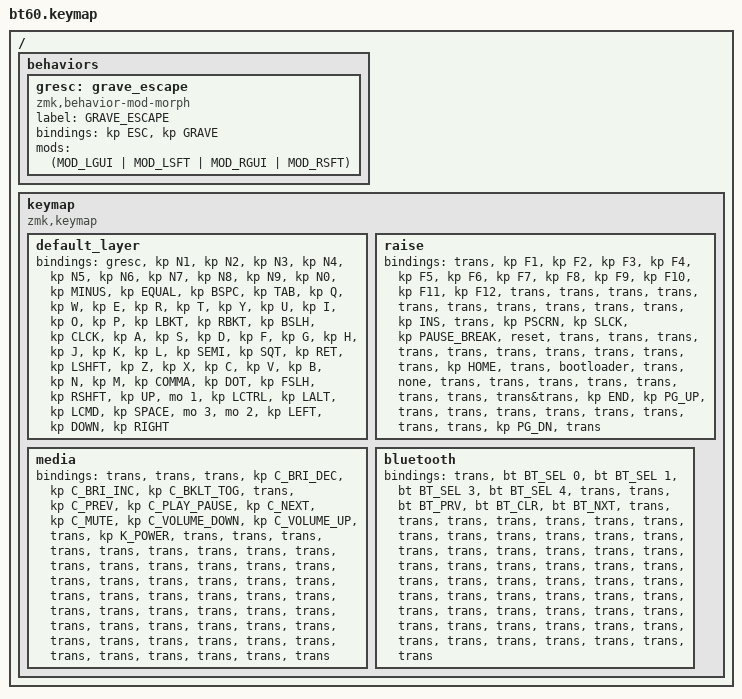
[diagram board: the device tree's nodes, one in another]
/*
 * Copyright (c) 2020 The ZMK Contributors
 *
 * SPDX-License-Identifier: MIT
 */


/* THIS FILE WAS GENERATED!
 *
 * This file was generated automatically. You may or may not want to
 * edit it directly.
 */

#include <behaviors.dtsi>
#include <dt-bindings/zmk/keys.h>

#include <dt-bindings/zmk/bt.h>
#include <dt-bindings/zmk/ext_power.h>

/ {
  
 behaviors
    {
    gresc:
        grave_escape
        {
            compatible = "zmk,behavior-mod-morph";
            label = "GRAVE_ESCAPE";
            #binding-cells = < 0>;
            bindings = <&kp ESC>, <&kp GRAVE>;
            mods = <(MOD_LGUI | MOD_LSFT | MOD_RGUI | MOD_RSFT)>;
        };
    };

    keymap {
        compatible = "zmk,keymap";


        default_layer {
            bindings = <
              &gresc &kp N1 &kp N2 &kp N3 &kp N4 &kp N5 &kp N6 &kp N7 &kp N8 &kp N9 &kp N0 &kp MINUS &kp EQUAL &kp BSPC

              &kp TAB &kp Q &kp W &kp E &kp R &kp T &kp Y &kp U &kp I &kp O &kp P &kp LBKT &kp RBKT &kp BSLH 

              &kp CLCK &kp A &kp S &kp D &kp F &kp G &kp H &kp J &kp K &kp L &kp SEMI &kp SQT &kp RET 

              &kp LSHFT &kp Z &kp X &kp C &kp V &kp B &kp N &kp M &kp COMMA &kp DOT &kp FSLH &kp RSHFT &kp UP &mo 1 

              &kp LCTRL &kp LALT &kp LCMD &kp SPACE &mo 3 &mo 2 &kp LEFT &kp DOWN &kp RIGHT
            >;
        };

        raise {
            bindings = <
              &trans &kp F1 &kp F2 &kp F3 &kp F4 &kp F5 &kp F6 &kp F7 &kp F8 &kp F9  &kp F10 &kp F11 &kp F12 &trans &trans 
              
              &trans &trans &trans &trans &trans &trans &trans &trans &kp INS &trans &kp PSCRN &kp SLCK &kp PAUSE_BREAK &reset 
              
              &trans &trans &trans &trans &trans &trans &trans &trans &trans &trans &kp HOME &trans &bootloader 

              &trans &none &trans &trans &trans &trans &trans &trans &trans &trans&trans &kp END &kp PG_UP &trans 

              &trans &trans &trans &trans &trans &trans &trans &kp PG_DN &trans 
          >;
        };

        media {
            bindings = <
          &trans &trans &trans &kp C_BRI_DEC &kp C_BRI_INC &kp C_BKLT_TOG &trans &kp C_PREV &kp C_PLAY_PAUSE &kp C_NEXT &kp C_MUTE &kp C_VOLUME_DOWN &kp C_VOLUME_UP &trans &kp K_POWER 
          &trans &trans &trans &trans &trans &trans &trans &trans &trans &trans &trans &trans &trans &trans &trans &trans &trans &trans &trans &trans &trans &trans &trans &trans &trans &trans &trans &trans &trans &trans &trans &trans &trans &trans &trans &trans &trans &trans &trans &trans &trans &trans &trans &trans &trans &trans &trans &trans &trans &trans &trans
          >;
        };

        bluetooth {
            bindings = <
          &trans &bt BT_SEL 0 &bt BT_SEL 1 &bt BT_SEL 3 &bt BT_SEL 4 &trans &trans &bt BT_PRV &bt BT_CLR &bt BT_NXT &trans &trans &trans &trans &trans &trans &trans &trans &trans &trans &trans &trans &trans &trans &trans &trans &trans &trans &trans &trans &trans &trans &trans &trans &trans &trans &trans &trans &trans &trans &trans &trans &trans &trans &trans &trans &trans &trans &trans &trans &trans &trans &trans &trans &trans &trans &trans &trans &trans &trans &trans &trans &trans &trans &trans &trans
          >;
        };
    };
};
